# M3351 register map
File version: 1.0
Registers are 32-bit, read-write, reset 0x0 unless marked. A register's access mark holds for its fields unless they carry their own. Offsets are from the block's base; [hi:lo] are bit positions; {n}, {i} and the like mark numbered series.

## CACHE — CACHE Register Map
Base 0x40036000
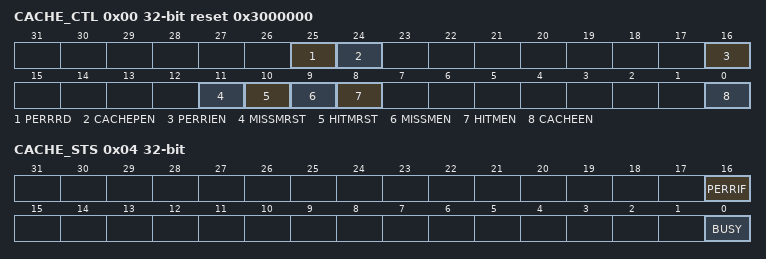
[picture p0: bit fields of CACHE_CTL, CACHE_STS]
0x00 CACHE_CTL reset 0x3000000 — CACHE Control Register
  [25] PERRRD — CACHE Parity Check Error Reload Data Control
    0=No action when cache parity check error; 1=Cache miss when cache parity check error
  [24] CACHEPEN — CACHE Parity Check Enable Bit
    0=Cache parity check Disabled; 1=Cache parity check Enabled
  [16] PERRIEN — CACHE Parity Check Error Interrupt Enable Bit
    0=Cache parity check error interrupt Disabled; 1=Cache parity check error interrupt Enabled
  [11] MISSMRST — Miss monitor reset
    0=No effect; 1=Reset the cache miss monitor
  [10] HITMRST — HIT monitor reset
    0=No effect; 1=Reset the cache hit monitor
  [9] MISSMEN — Miss Monitor Enable Bit
    0=Cache miss monitor stops counting and does not reset; 1=Cache miss monitor enabled
  [8] HITMEN — Hit Monitor Enable Bit
    0=Cache hit monitor stops counting and does not reset; 1=Cache hit monitor enabled
  [0] CACHEEN — Cache Enable Bit
    0=Cache Disabled; 1=Cache Enabled
0x04 CACHE_STS — CACHE Status Register
  [16] PERRIF — CACHE Parity Check Error Flag. This bit indicates the CACHE parity error occurred. Write 1 to clear this to 0.
    0=No CACHE parity error; 1=CACHE parity error occurred
  [0] BUSY — Cache Busy Flag (Read Only)
    0=Cache not busy on a invalidate operation; 1=Cache executing a invalidate operation
0x08 CACHE_HIT ro — CACHE Hit Monitor Register
  [31:0] Cachehitmonitor — Cache hit monitor counter.
0x0C CACHE_MISS ro — CACHE Miss Monitor Register
  [15:0] Cachemissmonitor — Cache miss monitor counter.
0x10 CACHE_ERRADDR ro — CACHE Parity Check Error Address Register
  [31:0] ERRADDR — CACHE Parity Error Address. This register shows CACHE parity error in accessing which word address.

## EBI — EBI Register Map
Base 0x40010000
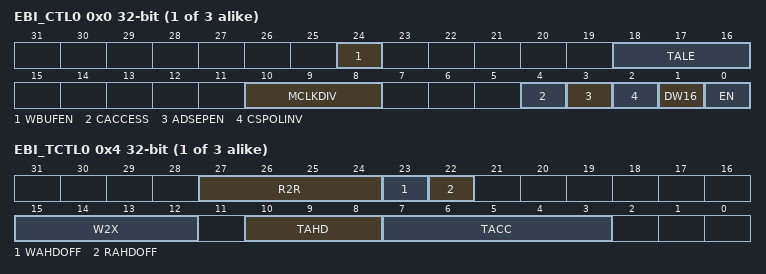
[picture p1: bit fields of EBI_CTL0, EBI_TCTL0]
{0x0+0x10*i} EBI_CTL{i} (i=0..2) — External Bus Interface Bank{i} Control Register
  [24] WBUFEN — EBI Write Buffer Enable Bit. Note: This bit is only available in EBI_CTL0 register.
    0=EBI write buffer Disabled; 1=EBI write buffer Enabled
  [18:16] TALE — Extend Time of ALE. The EBI_ALE high pulse period (tALE) to latch the address can be controlled by TALE. Note: This field is only available in EBI_CTL0 register.
  [10:8] MCLKDIV — External Output Clock Divider. The frequency of EBI output clock (MCLK) is controlled by MCLKDIV as follow:
    0=HCLK/1; 1=HCLK/2; 2=HCLK/4; 3=HCLK/8; 4=HCLK/16; 5=HCLK/32; 6=HCLK/64; 7=HCLK/128
  [4] CACCESS — Continuous Data Access Mode. When continuous access mode enabled, the tASU, tALE and tLHD cycles are bypass for continuous data transfer request.
    0=Continuous data access mode Disabled; 1=Continuous data access mode Enabled
  [3] ADSEPEN — EBI Address/Data Bus Separate Mode Enable Bit
    0=Address/Data Bus Separate Mode Disabled; 1=Address/Data Bus Separate Mode Enabled
  [2] CSPOLINV — Chip Select Pin Polar Inverse. This bit defines the active level of EBI chip select pin (EBI_nCS).
    0=Chip select pin (EBI_nCS) is active low; 1=Chip select pin (EBI_nCS) is active high
  [1] DW16 — EBI Data Width 16-bit Select. This bit defines if the EBI data width is 8-bit or 16-bit.
    0=EBI data width is 8-bit; 1=EBI data width is 16-bit
  [0] EN — EBI Enable Bit. This bit is the functional enable bit for EBI.
    0=EBI function Disabled; 1=EBI function Enabled
{0x4+0x10*i} EBI_TCTL{i} (i=0..2) — External Bus Interface Bank{i} Timing Control Register
  [27:24] R2R — Idle Cycle Between Read-to-read. This field defines the number of R2R idle cycle. When read action is finished and the next action is going to read, R2R idle cycle is inserted and EBI_nCS return to idle state.
  [23] WAHDOFF — Access Hold Time Disable Control When Write
    0=Data Access Hold Time (tAHD) during EBI writing Enabled; 1=Data Access Hold Time (tAHD) during EBI writing Disabled
  [22] RAHDOFF — Access Hold Time Disable Control When Read
    0=Data Access Hold Time (tAHD) during EBI reading Enabled; 1=Data Access Hold Time (tAHD) during EBI reading Disabled
  [15:12] W2X — Idle Cycle After Write. This field defines the number of W2X idle cycle. When write action is finished, W2X idle cycle is inserted and EBI_nCS return to idle state.
  [10:8] TAHD — EBI Data Access Hold Time. TAHD defines data access hold time (tAHD).
  [7:3] TACC — EBI Data Access Time. TACC defines data access time (tACC).
